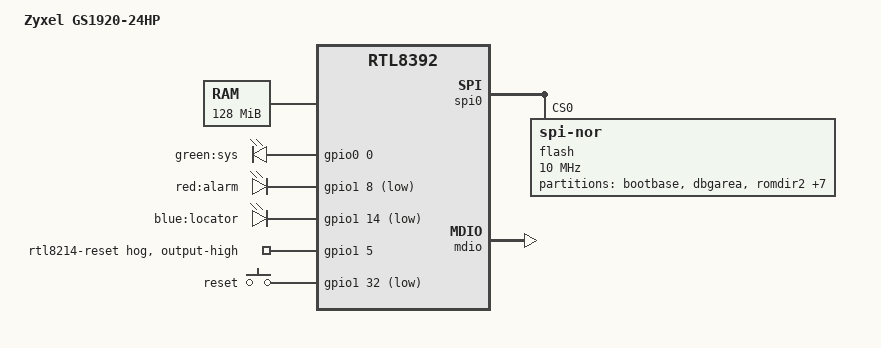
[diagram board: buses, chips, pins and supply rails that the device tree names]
/dts-v1/;

#include "rtl839x.dtsi"

#include <dt-bindings/input/input.h>
#include <dt-bindings/gpio/gpio.h>

/ {
	compatible = "zyxel,gs1900-24hp", "realtek,rtl8392-soc";
	model = "Zyxel GS1920-24HP";

	aliases {
		led-boot = &led_sys;
		led-failsafe = &led_sys;
		led-running = &led_sys;
		led-upgrade = &led_sys;
	};

	memory@0 {
		device_type = "memory";
		reg = <0x0 0x8000000>;
	};
/*
	chosen {
		stdout-path = "serial0:9600n8";
	};
*/

	leds {
		pinctrl-names = "default";
		pinctrl-0 = <&pinmux_disable_sys_led>;
		compatible = "gpio-leds";

		led_sys: sys {
			label = "green:sys";
			gpios = <&gpio0 0 GPIO_ACTIVE_HIGH>;
		};

		alarm {
			label = "red:alarm";
			gpios = <&gpio1 8 GPIO_ACTIVE_LOW>;
		};

		locator {
			label = "blue:locator";
			gpios = <&gpio1 14 GPIO_ACTIVE_LOW>;
		};
	};

	gpio1: rtl8231-gpio {
		compatible = "realtek,rtl8231-gpio";
		#gpio-cells = <2>;
		indirect-access-bus-id = <3>;
		gpio-controller;

		rtl8214-reset {
			gpio-hog;
			gpios = <5 GPIO_ACTIVE_HIGH>;
			output-high;
			line-name = "rtl8214-reset";
		};
	};

	keys {
		compatible = "gpio-keys-polled";
		poll-interval = <20>;

		mode {
			label = "reset";
			gpios = <&gpio1 32 GPIO_ACTIVE_LOW>;
			linux,code = <KEY_RESTART>;
		};
	};

	/* i2c of the left SFP cage: port 49 */
/*
	i2c0: i2c-gpio-0 {
		compatible = "i2c-gpio";
		sda-gpios = <&gpio1 24 (GPIO_ACTIVE_HIGH | GPIO_OPEN_DRAIN)>;
		scl-gpios = <&gpio1 25 (GPIO_ACTIVE_HIGH | GPIO_OPEN_DRAIN)>;
		i2c-gpio,delay-us = <2>;
		#address-cells = <1>;
		#size-cells = <0>;
	};

	sfp0: sfp-p9 {
		compatible = "sff,sfp";
		i2c-bus = <&i2c0>;
		los-gpio = <&gpio1 27 GPIO_ACTIVE_HIGH>;
		tx-fault-gpio = <&gpio1 22 GPIO_ACTIVE_HIGH>;
		mod-def0-gpio = <&gpio1 26 GPIO_ACTIVE_LOW>;
		tx-disable-gpio = <&gpio1 23 GPIO_ACTIVE_HIGH>;
	};
*/
	/* i2c of the right SFP cage: port 50 */
/*
	i2c1: i2c-gpio-1 {
		compatible = "i2c-gpio";
		sda-gpios = <&gpio1 30 (GPIO_ACTIVE_HIGH | GPIO_OPEN_DRAIN)>;
		scl-gpios = <&gpio1 31 (GPIO_ACTIVE_HIGH | GPIO_OPEN_DRAIN)>;
		i2c-gpio,delay-us = <2>;
		#address-cells = <1>;
		#size-cells = <0>;
	};

	sfp1: sfp-p10 {
		compatible = "sff,sfp";
		i2c-bus = <&i2c1>;
		los-gpio = <&gpio1 33 GPIO_ACTIVE_HIGH>;
		tx-fault-gpio = <&gpio1 28 GPIO_ACTIVE_HIGH>;
		mod-def0-gpio = <&gpio1 32 GPIO_ACTIVE_LOW>;
		tx-disable-gpio = <&gpio1 29 GPIO_ACTIVE_HIGH>;
	};
*/
};

&spi0 {
	status = "okay";
	flash@0 {
		compatible = "jedec,spi-nor";
		reg = <0>;
		spi-max-frequency = <10000000>;

		partitions {
			compatible = "fixed-partitions";
			#address-cells = <1>;
			#size-cells = <1>;

			partition@0 {
				label = "bootbase";
				reg = <0x0 0x20000>;
				read-only;
			};
			partition@20000 {
				label = "dbgarea";
				reg = <0x20000 0x10000>;
				read-only;
			};
			partition@30000 {
				label = "romdir2";
				reg = <0x30000 0x80000>;
				read-only;
			};
			partition@b0000 {
				reg = <0xb0000 0x710000>;
				label = "factory";

				compatible = "fixed-partitions";
				#address-cells = <1>;
				#size-cells = <1>;

				partition@0 {
					label = "loader";
					reg = <0x0 0x10000>;
				};

				partition@10000 {
					label = "firmware";
					reg = <0x10000 0x700000>;
					compatible = "openwrt,uimage", "denx,uimage";
				};
			};
			partition@7c0000 {
				label = "logarea1";
				reg = <0x7c0000 0x20000>;
				read-only;
			};
			partition@7e0000 {
				label = "logarea2";
				reg = <0x7e0000 0x20000>;
				read-only;
			};
			partition@830000 {
				label = "romdir2a";
				reg = <0x830000 0x80000>;
			};
			partition@8b0000 {
				label = "firmware2";
				reg = <0x8b0000 0x710000>;
			};
		};
	};
};

&ethernet0 {
	mdio: mdio-bus {
		compatible = "realtek,rtl838x-mdio";
		regmap = <&ethernet0>;
		#address-cells = <1>;
		#size-cells = <0>;

		/* External phy RTL8218B #1 */
		EXTERNAL_PHY(0)
		EXTERNAL_PHY(1)
		EXTERNAL_PHY(2)
		EXTERNAL_PHY(3)
		EXTERNAL_PHY(4)
		EXTERNAL_PHY(5)
		EXTERNAL_PHY(6)
		EXTERNAL_PHY(7)

		/* External phy RTL8218B #2 */
		EXTERNAL_PHY(8)
		EXTERNAL_PHY(9)
		EXTERNAL_PHY(10)
		EXTERNAL_PHY(11)
		EXTERNAL_PHY(12)
		EXTERNAL_PHY(13)
		EXTERNAL_PHY(14)
		EXTERNAL_PHY(15)

		/* External phy RTL8218B #3 */
		EXTERNAL_PHY(16)
		EXTERNAL_PHY(17)
		EXTERNAL_PHY(18)
		EXTERNAL_PHY(19)
		EXTERNAL_PHY(20)
		EXTERNAL_PHY(21)
		EXTERNAL_PHY(22)
		EXTERNAL_PHY(23)

		/* RTL8392 Internal SerDes */

		EXTERNAL_SFP_PHY(48)
		EXTERNAL_SFP_PHY(49)
		EXTERNAL_SFP_PHY(50)
		EXTERNAL_SFP_PHY(51)

	};
};

&switch0 {
	ports {
		#address-cells = <1>;
		#size-cells = <0>;

		SWITCH_PORT_SDS(0, 01, qsgmii, 0, 1)
		SWITCH_PORT(1, 02, qsgmii)
		SWITCH_PORT(2, 03, qsgmii)
		SWITCH_PORT(3, 04, qsgmii)
		SWITCH_PORT_SDS(4, 05, qsgmii, 1, 0)
		SWITCH_PORT(5, 06, qsgmii)
		SWITCH_PORT(6, 07, qsgmii)
		SWITCH_PORT(7, 08, qsgmii)

		SWITCH_PORT_SDS(8, 09, qsgmii, 2, 3)
		SWITCH_PORT(9, 10, qsgmii)
		SWITCH_PORT(10, 11, qsgmii)
		SWITCH_PORT(11, 12, qsgmii)
		SWITCH_PORT_SDS(12, 13, qsgmii, 3, 2)
		SWITCH_PORT(13, 14, qsgmii)
		SWITCH_PORT(14, 15, qsgmii)
		SWITCH_PORT(15, 16, qsgmii)

		SWITCH_PORT_SDS(16, 17, qsgmii, 4, 5)
		SWITCH_PORT(17, 18, qsgmii)
		SWITCH_PORT(18, 19, qsgmii)
		SWITCH_PORT(19, 20, qsgmii)
		SWITCH_PORT_SDS(20, 21, qsgmii, 5, 4)
		SWITCH_PORT(21, 22, qsgmii)
		SWITCH_PORT(22, 23, qsgmii)
		SWITCH_PORT(23, 24, qsgmii)

		SWITCH_PORT_SDS(48, 25, qsgmii, 12, 12)
		SWITCH_PORT(49, 26, qsgmii)
		SWITCH_PORT(50, 27, qsgmii)
		SWITCH_PORT(51, 28, qsgmii)

		/* CPU-Port */
		port@52 {
			ethernet = <&ethernet0>;
			reg = <52>;
			phy-mode = "qsgmii";
			fixed-link {
				speed = <1000>;
				full-duplex;
			};
		};
	};
};

#define _MASK_ 1
#define _WAIT_ 2

&serdes0 {
	controlled-ports = <0x3fff>;
	cmd-setup = /bits/ 16 <
		/* 5g SerDes patch (ports 0-7, 10-11) */
		_MASK_ 0x0cff 0x08 0x11 0x0000 0x8000
		_MASK_ 0x0cff 0x08 0x11 0x1000 0x7000
		_MASK_ 0x0cff 0x08 0x11 0x0400 0x0e00
		_MASK_ 0x0cff 0x08 0x11 0x00c0 0x01c0
		_MASK_ 0x0cff 0x08 0x16 0x0000 0x8000
		_MASK_ 0x0cff 0x08 0x08 0x0000 0x0008
		_MASK_ 0x0cff 0x08 0x07 0x0000 0x0200
		_MASK_ 0x0cff 0x08 0x07 0x0000 0x0100
		_MASK_ 0x0cff 0x08 0x14 0x0002 0x0002
		_MASK_ 0x0cff 0x08 0x15 0xc000 0xf000
		_MASK_ 0x0cff 0x08 0x16 0x0000 0x1000
		_MASK_ 0x0cff 0x08 0x18 0x0006 0x003f
		_MASK_ 0x0cff 0x08 0x08 0x0000 0x0040
		_MASK_ 0x0cff 0x08 0x08 0x0000 0x0800
		_MASK_ 0x0cff 0x08 0x08 0x8000 0xf000
		_MASK_ 0x0cff 0x08 0x08 0x0400 0x0780	
		/* 5g clock edge (ports 10-11) */
		_MASK_ 0x0c00 0x00 0x07 0x4000 0x4000
		/* 5g full swing (ports 4, 10) */
		_MASK_ 0x0410 0x08 0x08 0x8c6a 0xffff
		/* 10g digital patch (ports 8-9, 12-13) */
		_MASK_ 0x3300 0x0a 0x00 0x5800 0xffff 
		_MASK_ 0x3300 0x0a 0x01 0x4000 0xffff 
		_MASK_ 0x1100 0x0a 0x02 0x5400 0xffff 
		_MASK_ 0x2200 0x0a 0x02 0x5000 0xffff 
		_MASK_ 0x3300 0x0a 0x03 0x0000 0xffff 
		_MASK_ 0x3300 0x0a 0x04 0x0000 0xffff 
		_MASK_ 0x3300 0x0a 0x05 0x4000 0xffff 
		_MASK_ 0x3300 0x0a 0x06 0x4000 0xffff 
		_MASK_ 0x3300 0x0a 0x07 0xffff 0xffff 
		_MASK_ 0x3300 0x0a 0x08 0xffff 0xffff 
		_MASK_ 0x3300 0x0a 0x09 0x806f 0xffff 
		_MASK_ 0x3300 0x0a 0x0a 0x0004 0xffff 
		_MASK_ 0x3300 0x0a 0x0b 0x0000 0xffff 
		_MASK_ 0x3300 0x0a 0x0c 0x0000 0xffff 
		_MASK_ 0x3300 0x0a 0x0d 0x0000 0xffff 
		_MASK_ 0x3300 0x0a 0x0e 0x0a00 0xffff 
		_MASK_ 0x3300 0x0a 0x0f 0x2000 0xffff 
		_MASK_ 0x3300 0x0a 0x10 0xf00e 0xffff 
		_MASK_ 0x1100 0x0a 0x11 0xf04a 0xffff 
		_MASK_ 0x2200 0x0a 0x11 0xfdab 0xffff 
		_MASK_ 0x1100 0x0a 0x12 0x97b3 0xffff 
		_MASK_ 0x2200 0x0a 0x12 0x96ea 0xffff 
		_MASK_ 0x3300 0x0a 0x13 0x5318 0xffff 
		_MASK_ 0x3300 0x0a 0x14 0x0f03 0xffff 
		_MASK_ 0x3300 0x0a 0x15 0x0000 0xffff 
		_MASK_ 0x3300 0x0a 0x16 0x0000 0xffff 
		_MASK_ 0x3300 0x0a 0x17 0x0000 0xffff 
		_MASK_ 0x3300 0x0a 0x18 0x0000 0xffff 
		_MASK_ 0x3300 0x0a 0x19 0x0000 0xffff 
		_MASK_ 0x3300 0x0a 0x1a 0xffff 0xffff 
		_MASK_ 0x3300 0x0a 0x1b 0x0000 0xffff 
		_MASK_ 0x3300 0x0a 0x1c 0x1203 0xffff 
		_MASK_ 0x3300 0x0a 0x1d 0x0000 0xffff 
		_MASK_ 0x3300 0x0a 0x1e 0xa052 0xffff 
		_MASK_ 0x3300 0x0a 0x1f 0x9a00 0xffff 
		_MASK_ 0x3300 0x0b 0x00 0x00f5 0xffff 
		_MASK_ 0x3300 0x0b 0x01 0xf000 0xffff 
		_MASK_ 0x1100 0x0b 0x02 0x41ff 0xffff 
		_MASK_ 0x2200 0x0b 0x02 0x4079 0xffff 
		_MASK_ 0x3300 0x0b 0x03 0x0000 0xffff 
		_MASK_ 0x1100 0x0b 0x04 0x39ff 0xffff 
		_MASK_ 0x2200 0x0b 0x04 0x93fa 0xffff 
		_MASK_ 0x3300 0x0b 0x05 0x3340 0xffff 
		_MASK_ 0x1100 0x0b 0x06 0x40aa 0xffff 
		_MASK_ 0x2200 0x0b 0x06 0x4280 0xffff 
		_MASK_ 0x3300 0x0b 0x07 0x0000 0xffff 
		_MASK_ 0x3300 0x0b 0x08 0x801f 0xffff 
		_MASK_ 0x3300 0x0b 0x09 0x0000 0xffff 
		_MASK_ 0x3300 0x0b 0x0a 0x619c 0xffff 
		_MASK_ 0x3300 0x0b 0x0b 0xffed 0xffff 
		_MASK_ 0x3300 0x0b 0x0c 0x29ff 0xffff 
		_MASK_ 0x3300 0x0b 0x0d 0x29ff 0xffff 
		_MASK_ 0x1100 0x0b 0x0e 0x4e10 0xffff 
		_MASK_ 0x2200 0x0b 0x0e 0x4c50 0xffff 
		_MASK_ 0x1100 0x0b 0x0f 0x4e10 0xffff 
		_MASK_ 0x2200 0x0b 0x0f 0x4c50 0xffff 
		_MASK_ 0x3300 0x0b 0x10 0x0000 0xffff 
		_MASK_ 0x3300 0x0b 0x11 0x0000 0xffff 
		_MASK_ 0x3300 0x00 0x0c 0x08ec 0xffff 
		_MASK_ 0x2200 0x0b 0x1f 0x003f 0xffff 
		_MASK_ 0x3300 0x00 0x07 0x4000 0x4000 
		/* 10g analog patch (ports 8-9, 12-13) */
		_MASK_ 0x3300 0x0b 0x09 0x417f 0xffff 
		_MASK_ 0x3300 0x0a 0x1c 0x0000 0x0200 
		_MASK_ 0x3300 0x0a 0x1c 0x0000 0x1c00 
		_MASK_ 0x3300 0x0a 0x1c 0x0028 0x0038 
		_MASK_ 0x3300 0x0a 0x1c 0x0000 0x01c0 
		_MASK_ 0x3300 0x0a 0x1c 0x0002 0x0007 
		_MASK_ 0x3300 0x0b 0x01 0xc440 0xffff 
		_MASK_ 0x1100 0x0b 0x06 0x0000 0x0008 
		_MASK_ 0x3300 0x0a 0x05 0x8000 0xffff 
		_MASK_ 0x3300 0x0a 0x06 0x8000 0xffff 
		_MASK_ 0x3300 0x0a 0x0a 0x0000 0xffff 
		_MASK_ 0x3300 0x0a 0x1e 0x0002 0xffff 
		_MASK_ 0x3300 0x0a 0x1f 0xbe00 0xffff 
		_MASK_ 0x1100 0x0b 0x0e 0x0000 0x0400 
		_MASK_ 0x1100 0x0b 0x0f 0x0000 0x0400 
		_MASK_ 0x1100 0x0b 0x0e 0x0000 0x4000 
		_MASK_ 0x1100 0x0b 0x0f 0x0000 0x4000 
		_MASK_ 0x3300 0x0a 0x10 0x0000 0x0020 
		_MASK_ 0x3300 0x0b 0x09 0x0000 0x0100 
		_MASK_ 0x3300 0x0a 0x03 0xf000 0xf000 
		_MASK_ 0x3300 0x0a 0x1f 0x3000 0x3000 
		_MASK_ 0x3300 0x0a 0x1f 0x0e00 0x0e00 
		_MASK_ 0x3300 0x0b 0x01 0x8000 0x8000 
		_MASK_ 0x3300 0x0b 0x01 0x4000 0x4000 
		_MASK_ 0x3300 0x0b 0x01 0x0000 0x2000 
		_MASK_ 0x3300 0x0b 0x01 0x0000 0x1000 
		_MASK_ 0x3300 0x0b 0x01 0x0400 0x0e00 
		_MASK_ 0x3300 0x0b 0x01 0x0080 0x01c0 
		_MASK_ 0x3300 0x0b 0x01 0x0000 0x0038 
		_MASK_ 0x3300 0x0b 0x01 0x0000 0x0007 
		_MASK_ 0x3300 0x0b 0x0c 0x0200 0x0200 
		_MASK_ 0x3300 0x0b 0x0d 0x0200 0x0200 
		_MASK_ 0x3300 0x0b 0x08 0x0020 0x0020 
		_MASK_ 0x3300 0x0b 0x08 0x0000 0x0040 
		_MASK_ 0x3300 0x0a 0x1c 0x0000 0x8000 
		_MASK_ 0x3300 0x0a 0x10 0x0000 0xf000 
		_MASK_ 0x3300 0x0a 0x13 0x0000 0x0010 
		_MASK_ 0x3300 0x0a 0x13 0x0000 0x0200 
		_MASK_ 0x3300 0x0a 0x13 0x0008 0x000f 
		_MASK_ 0x3300 0x0a 0x13 0x0100 0x01e0 
		>;
};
